# DMASS_PSILCFG_0_DMASS_PSILCFG_0_PSILCFG_PROXY_48130000h register map
Vendor: Texas Instruments
Peripheral module from a debugger description file (folder am62L).
Registers are 32-bit, read-write, reset 0x0 unless marked. A register's access mark holds for its fields unless they carry their own. Offsets are as the file gives them; lines under a group give offsets from that group; [hi:lo] are bit positions; {n}, {i} and the like mark numbered series; 'fields as' and 'values as' point back to an identical list; <NAME> marks a mode.

## DMASS_PSILCFG_0_PSILCFG_PROXY
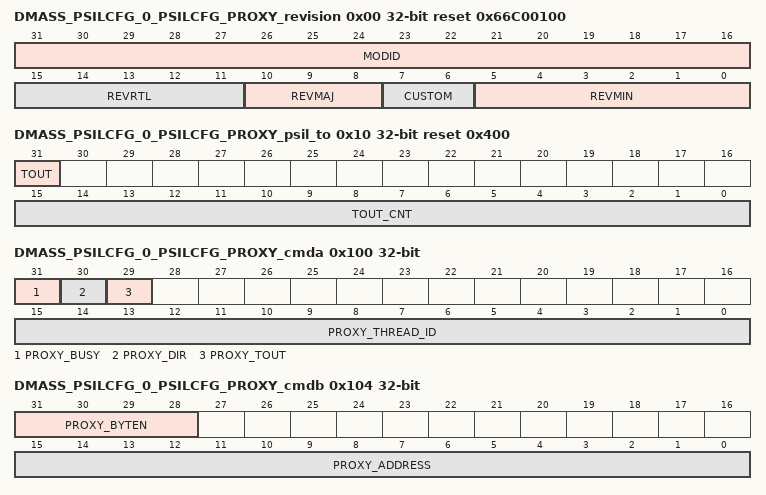
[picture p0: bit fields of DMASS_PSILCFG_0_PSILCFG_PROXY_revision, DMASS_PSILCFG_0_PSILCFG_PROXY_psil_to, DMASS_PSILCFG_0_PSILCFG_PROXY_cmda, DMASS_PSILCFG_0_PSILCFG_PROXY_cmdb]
0x00 DMASS_PSILCFG_0_PSILCFG_PROXY_revision ro reset 0x66C00100 — The Revision Register contains the major and minor revisions for the module.
  [31:16] MODID — Module ID field Reset Source: srst_n
  [15:11] REVRTL — RTL revision. Will vary depending on release. Reset Source: srst_n
  [10:8] REVMAJ — Major revision Reset Source: srst_n
  [7:6] CUSTOM — Custom Reset Source: srst_n
  [5:0] REVMIN — Minor revision Reset Source: srst_n
0x10 DMASS_PSILCFG_0_PSILCFG_PROXY_psil_to reset 0x400 — The PSI-L proxy timeout register controls the timeout watchdog and reports timeout occurrances on PSI-L configuration transactions issued by the built in PSI-L proxy.
  [31] TOUT — Timeout occurred. When set indicates that a timeout has occurred on a config access. Once set, this bit is persistent until manually cleared Reset Source: srst_n
  [15:0] TOUT_CNT — Timeout period. Specifies how many cycles to wait before closing up a conifiguration read or write transaction and asserting the tout bit Reset Source: srst_n
0x100 DMASS_PSILCFG_0_PSILCFG_PROXY_cmda — The Command Register A contains the busy indicator, direction, and thread number for the configuration transaction.
  [31] PROXY_BUSY — Indication that a configuration read or write is in progress 0 No transaction is in progress1 Transaction is in progress
  [30] PROXY_DIR — Direction of configuration transaction 0 Write transaction1 Read transaction
  [29] PROXY_TOUT — Indication that a timeout occurred. This bit should be written to 0 on each new transaction. 0 Transaction completed normally1 Timeout Occurred
  [15:0] PROXY_THREAD_ID — Thread ID to which configuration read or write is being sent Reset Source: srst_n
0x104 DMASS_PSILCFG_0_PSILCFG_PROXY_cmdb — The Command Register B contains the byte enables and word address for the configuration transaction.
  [31:28] PROXY_BYTEN — Byte enables to use for configuration read or write Reset Source: srst_n
  [15:0] PROXY_ADDRESS — Word (32-bit) address within thread configuration space for transaction 0 Peer thread ID register. Implemented for src threads only.1 Peer credit register. Implemented for src threads only.2 Enable register64 Capabilities register1024 Static TR register
0x108 DMASS_PSILCFG_0_PSILCFG_PROXY_wdata — The Write Data Register contains the data which is to be written during the configuration transaction.
  [31:0] PROXY_WDATA — Configuration data word to be written Reset Source: srst_n
0x140 DMASS_PSILCFG_0_PSILCFG_PROXY_rdata — The Read Data Register contains the data which which was read back during the configuration transaction.
  [31:0] PROXY_RDATA — Configuration data word that was read Reset Source: srst_n
